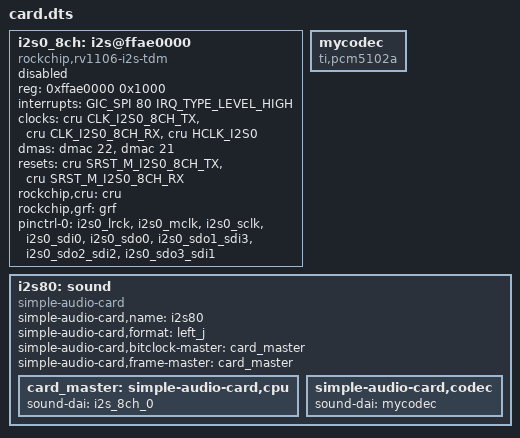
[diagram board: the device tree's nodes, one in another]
i2s0_8ch: i2s@ffae0000 {
    compatible = "rockchip,rv1106-i2s-tdm";
    reg = <0xffae0000 0x1000>;
    interrupts = <GIC_SPI 80 IRQ_TYPE_LEVEL_HIGH>;

    clocks = <&cru CLK_I2S0_8CH_TX>, <&cru CLK_I2S0_8CH_RX>, <&cru HCLK_I2S0>;
//    clocks = <&cru MCLK_I2S0_8CH_TX>, <&cru MCLK_I2S0_8CH_RX>, <&cru HCLK_I2S0>;
    clock-names = "mclk_tx", "mclk_rx", "hclk";

    dmas = <&dmac 22>, <&dmac 21>;
    dma-names = "tx", "rx";
    resets = <&cru SRST_M_I2S0_8CH_TX>, <&cru SRST_M_I2S0_8CH_RX>;
    reset-names = "tx-m", "rx-m";

//    rockchip,clk-trcm = <1>;
//    rockchip,playback-only;

    #sound-dai-cells = <0>;
    rockchip,cru = <&cru>;
    rockchip,grf = <&grf>;
    pinctrl-names = "default";
    pinctrl-0 = <&i2s0_lrck
        &i2s0_mclk
        &i2s0_sclk
        &i2s0_sdi0
        &i2s0_sdo0
        &i2s0_sdo1_sdi3
        &i2s0_sdo2_sdi2
        &i2s0_sdo3_sdi1>;
    status = "disabled";

//    assigned-clocks = <&cru CLK_I2S0_8CH_TX>, <&cru CLK_I2S0_8CH_RX>;
//    assigned-clock-parents = <&i2s0_mclkin>, <&i2s0_mclkin>;

};

mycodec: mycodec {
    compatible = "ti,pcm5102a";
    #sound-dai-cells = <0>;
    status = "okay";
};

i2s80:sound {
	compatible = "simple-audio-card";
	simple-audio-card,name = "i2s80";

	simple-audio-card,format = "left_j";

    simple-audio-card,bitclock-master = <&card_master>;
    simple-audio-card,frame-master = <&card_master>;

    card_master: simple-audio-card,cpu {
            sound-dai = <&i2s_8ch_0>;

	    // mclk output enable, move to i2s0
//!!!	    clocks = <&cru MCLK_I2S0_8CH_TX>;
        };

        simple-audio-card,codec {
            sound-dai = <&mycodec>;

        };
};
